# JN5179 register map
Vendor: NXP; Series: JN517x; File version: 20150316
CPU: CM3 r2p1, little endian, no MPU, no FPU, 4 interrupt priority bits
Registers are 32-bit, read-write, reset 0x0 unless marked. A register's access mark holds for its fields unless they carry their own. Offsets are from the block's base; [hi:lo] are bit positions; {n}, {i} and the like mark numbered series.

## SYS_CTRL — System Controller
Base 0x40000000
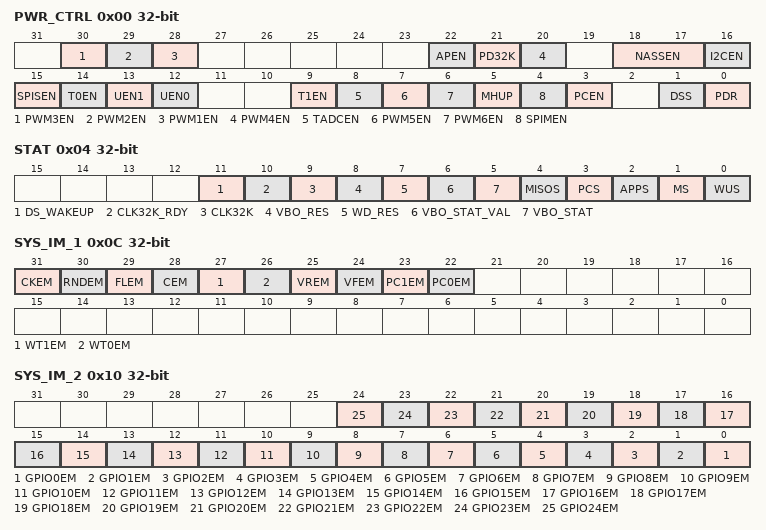
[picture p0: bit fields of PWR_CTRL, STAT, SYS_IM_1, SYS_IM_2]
0x00 PWR_CTRL — Power Control Register
  [30] PWM3EN — Enable PWM3 Timer
    0=Disable (PWM3 Timer is disabled); 1=Enable (PWM3 Timer is enabled)
  [29] PWM2EN — Enable PWM2 Timer
    0=Disable (PWM2 Timer is disabled); 1=Enable (PWM2 Timer is enabled)
  [28] PWM1EN — Enable PWM1 Timer
    0=Disable (PWM1 Timer is disabled); 1=Enable (PWM1 Timer is enabled)
  [22] APEN — Enable Analogue Peripheral Power
    0=Disable (Analogue periperal power is disabled); 1=Enable (Analogue periperal power is enabled)
  [21] PD32K — Power Down 32kHz Oscillator during sleep
    0=Disable (32kHz Oscillator remains powered during sleep); 1=Enable (32kHz Oscillator is powered down during sleep)
  [20] PWM4EN — Enable PWM4 Timer
    0=Disable (PWM4 Timer is disabled); 1=Enable (PWM4 Timer is enabled)
  [18:17] NASSEN — Number of additional SPI slave selects
    0=SPI slave select available for DIO6 (depending on DIO configuration); 1=SPI slave select available for DIO6, DIO15 (depending on DIO configuration); 2=SPI slave select available for DIO6, DIO7 (depending on DIO configuration)
  [16] I2CEN — Enable I2C Interface
    0=Disable (I2C interface is disabled); 1=Enable (I2C interface is enabled)
  [15] SPISEN — Enable SPI Slave
    0=Disable (SPI slave is disabled); 1=Enable (SPI slave is enabled)
  [14] T0EN — Enable Timer 0
    0=Disable (Timer 0 is disabled); 1=Enable (Timer 0 is enabled)
  [13] UEN1 — Enable UART 1
    0=Disable (UART 1 is disabled); 1=Enable (UART 1 is enabled)
  [12] UEN0 — Enable UART 0
    0=Disable (UART 0 is disabled); 1=Enable (UART 0 is enabled)
  [9] T1EN — Enable Timer 1
    0=Disable (Timer 1 is disabled); 1=Enable (Timer 1 is enabled)
  [8] TADCEN — Enable ADC Timer
    0=Disable (ADC timer is disabled); 1=Enable (ADC timer is enabled)
  [7] PWM5EN — Enable PWM5 Timer
    0=Disable (PWM5 timer is disabled); 1=Enable (PWM5 timer is enabled)
  [6] PWM6EN — Enable PWM6 Timer
    0=Disable (PWM6 timer is disabled); 1=Enable (PWM6 timer is enabled)
  [5] MHUP — Memory Hold Up
    0=Disable (RAM is powered down during sleep); 1=Enable (RAM remains powered during sleep)
  [4] SPIMEN — SPI Master Enable
    0=Disable (SPI master disabled); 1=Enable (SPI master enabled)
  [3] PCEN — Protocol Clock Enable
    0=Disable (Protocol clock disabled); 1=Enable (Protocol clock enabled)
  [1] DSS — Deep sleep request
    0=Sleep (Select normal sleep mode); 1=DeepSleep (Select deep sleep mode)
  [0] PDR — Power Down Request (once set the chip begins power down sequence and it must not be cleared)
    0=Disable (Power down not requested); 1=Enable (Power down requested)
0x04 STAT — Device Status Register
  [11] DS_WAKEUP — Deep sleep wake up
    0=Disabled (Normal power up); 1=Enabled (Power up was from deep sleep mode)
  [10] CLK32K_RDY — Status of the 32kHz system clock
    0=Clock is not running; 1=Clock is running satisfactorily
  [9] CLK32K — Instantaneous value of the 32kHz system clock
    0=Clock is low; 1=Clock is high
  [8] VBO_RES — Voltage Brown Out Reset Event
    0=Disabled (Normal power up); 1=Enabled (Power up was proceeded by a voltage brown out)
  [7] WD_RES — Watchdog Reset Event
    0=Disabled (Normal power up); 1=Enabled (Power up was proceeded by a watchdog timeout)
  [6] VBO_STAT_VAL — Voltage Brown Out Status Valid
    0=Disabled (Voltage brown out status is invalid); 1=Enabled (Voltage brown out status is valid)
  [5] VBO_STAT — Voltage Brown Out Status
    0=Disabled (Supply voltage is greater than VBO threshold); 1=Enabled (Supply voltage is lower than VBO threshold)
  [4] MISOS — Value of SPIMISO pin
    0=Disabled (SPIMISO pin is low); 1=Enabled (SPIMISO pin is high)
  [3] PCS — IEEE802.15.4 Radio Clock Status
    0=Disabled (Protocol clock is stopped); 1=Enabled (Protocol clock is running)
  [2] APPS — Analogue Periperhal Power Status
    0=Disabled (Analogue peripherals are powered up); 1=Enabled (Analogue peripherals are powered off)
  [1] MS — Memory Status
    0=MemoryClear (Memory was powered down during sleep); 1=MemoryHeld (Memory was held during sleep)
  [0] WUS — Wake Up Status
    0=ColdStart (Device cold start); 1=WarmStart (Device warm start)
0x0C SYS_IM_1 — System Interrrupt Mask 1 - Enable system controller interrupt sources
  [31] CKEM — Clock Change Event Mask
    0=Disabled (Clock Change Interrupt Disabled); 1=Enabled (Clock Change Interrupt Enabled)
  [30] RNDEM — Random Number Generator Event Mask
    0=Disabled (Random Number Generator Interrupt Disabled); 1=Enabled (Random Number Generator Interrupt Enabled)
  [29] FLEM — Flash Controller Event Mask
    0=Disabled (Flash Controller Interrupt Disabled); 1=Enabled (Flash Controller Interrupt Enabled)
  [28] CEM — Comparator Event Mask
    0=Disabled (Comparator Interrupt Disabled); 1=Enabled (Comparator Interrupt Enabled)
  [27] WT1EM — Wake Up Timer 1 Event Mask
    0=Disabled (Wake Up Timer 1 Interrupt Disabled); 1=Enabled (Wake Up Timer 1 Interrupt Enabled)
  [26] WT0EM — Wake Up Timer 0 Event Mask
    0=Disabled (Wake Up Timer 0 Interrupt Disabled); 1=Enabled (Wake Up Timer 0 Interrupt Enabled)
  [25] VREM — VBO Rising Event Mask (Voltage moved below threshold)
    0=Disabled (VBO Rising Interrupt Disabled); 1=Enabled (VBO Rising Interrupt Enabled)
  [24] VFEM — VBO Falling Event Mask (Voltage moved above threshold)
    0=Disabled (VBO Falling Interrupt Disabled); 1=Enabled (VBO Falling Interrupt Enabled)
  [23] PC1EM — Pulse Counter 1 Event Mask
    0=Disabled (Pulse Counter 1 Interrupt Disabled); 1=Enabled (Pulse Counter 1 Interrupt Enabled)
  [22] PC0EM — Pulse Counter 0 Event Mask
    0=Disabled (Pulse Counter 0 Interrupt Disabled); 1=Enabled (Pulse Counter 0 Interrupt Enabled)
0x10 SYS_IM_2 — System Interrrupt Mask 2 - Enable system controller interrupt sources
  [n] GPIO{n}EM (n=0..24) — GPIO{n} Event Mask
    0=Disabled (GPIO{n} Interrupt Disabled); 1=Enabled (GPIO{n} Interrupt Enabled)
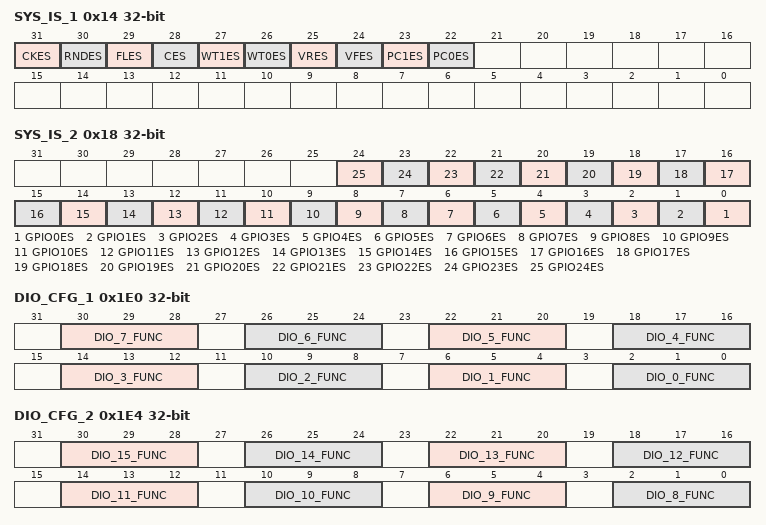
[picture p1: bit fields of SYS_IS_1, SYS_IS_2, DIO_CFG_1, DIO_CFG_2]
0x14 SYS_IS_1 — System Interrrupt Status 1 - system controller interrupt status
  [31] CKES — Clock Change Event Status
    0=Clear (Clock Change No Interrupt); 1=Flagged (Clock Change Interrupt Flagged)
  [30] RNDES — Random Number Generator Event Status
    0=Clear (Random Number Generator No Interrupt); 1=Flagged (Random Number Generator Interrupt Flagged)
  [29] FLES — Flash Controller Event Status
    0=Clear (Flash Controller No Interrupt); 1=Flagged (Flash Controller Interrupt Flagged)
  [28] CES — Comparator Event Status
    0=Clear (Comparator No Interrupt); 1=Flagged (Comparator Interrupt Flagged)
  [27] WT1ES — Wake Up Timer 1 Event Status
    0=Clear (Wake Up Timer 1 No Interrupt); 1=Flagged (Wake Up Timer 1 Interrupt Flagged)
  [26] WT0ES — Wake Up Timer 0 Event Status
    0=Clear (Wake Up Timer 0 No Interrupt); 1=Flagged (Wake Up Timer 0 Interrupt Flagged)
  [25] VRES — VBO Rising Event Status (Voltage moved below threshold)
    0=Clear (VBO Rising No Interrupt); 1=Flagged (VBO Rising Interrupt Flagged)
  [24] VFES — VBO Falling Event Status (Voltage moved above threshold)
    0=Clear (VBO Falling No Interrupt); 1=Flagged (VBO Falling Interrupt Flagged)
  [23] PC1ES — Pulse Counter 1 Event Status
    0=Clear (Pulse Counter 1 No Interrupt); 1=Flagged (Pulse Counter 1 Interrupt Flagged)
  [22] PC0ES — Pulse Counter 0 Event Status
    0=Clear (Pulse Counter 0 No Interrupt); 1=Flagged (Pulse Counter 0 Interrupt Flagged)
0x18 SYS_IS_2 — System Interrrupt Status 2 - system controller interrupt status
  [n] GPIO{n}ES (n=0..24) — GPIO{n} Event Status
    0=Clear (GPIO{n} No Interrupt); 1=Flagged (GPIO{n} Interrupt Flagged)
0x1E0 DIO_CFG_1 — DIO Configuration 1
  [30:28] DIO_7_FUNC — DIO7 Function
    0=GPIO (DIO7 functions as GPIO); 2=SPI_M_MOSI (DIO7 functions as SPI master MOSI); 3=TDI (DIO7 functions as JTAG TDI); 4=SPI_M_SEL2 (DIO7 functions as SPI master chip select 2); 5=SPI_S_SEL (DIO7 functions as SPI slave chip select); 6=COMP_OUT (DIO7 functions as comparator output)
  [26:24] DIO_6_FUNC — DIO6 Function
    0=GPIO (DIO6 functions as GPIO); 1=TIM1_CAP (DIO6 functions as timer 1 capture input); 2=SPI_M_SEL0 (DIO6 functions as SPI master chip select 0); 3=TCK (DIO6 functions as JTAG TCK / SWCK); 4=UART0_CTS (DIO6 functions as UART0 CTS); 5=SPI_S_SCK (DIO6 functions as SPI slave SCK); 7=UART1_RX (DIO6 functions as UART1 RX)
  [22:20] DIO_5_FUNC — DIO5 Function
    0=GPIO (DIO5 functions as GPIO); 1=UART0_TX (DIO5 functions as UART0 TX); 2=TIM0_CAP (DIO5 functions as timer 0 capture intput); 3=I2C_SDA (DIO5 functions as I2C SDA); 4=ADE (DIO5 functions as antenna diversity even output); 5=PC1 (DIO5 functions as pulse counter 1 intput)
  [18:16] DIO_4_FUNC — DIO4 Function
    0=GPIO (DIO4 functions as GPIO); 1=UART0_RX (DIO4 functions as UART0 RX); 2=TIM0_GT (DIO4 functions as timer 0 clock gate); 3=I2C_SCL (DIO4 functions as I2C SCL); 4=ADO (DIO4 functions as antenna diversity odd output)
  [14:12] DIO_3_FUNC — DIO3 Function
    0=GPIO (DIO3 functions as GPIO); 1=RFTX (DIO3 functions as RFTX); 2=TIM0_OUT (DIO3 functions as timer 0 output); 3=I2C_SCL (DIO3 functions as I2C SCL); 5=UART1_TX (DIO3 functions as UART 1 TX); 6=PWM4 (DIO3 functions as PWM4 output)
  [10:8] DIO_2_FUNC — DIO2 Function
    0=GPIO (DIO2 functions as GPIO); 1=RFRX (DIO2 functions as RFRX); 2=TIM0_CAP (DIO2 functions as timer 0 capture input); 3=I2C_SDA (DIO2 functions as I2C SDA); 5=UART1_RX (DIO2 functions as UART 1 RX)
  [6:4] DIO_1_FUNC — DIO1 Function
    0=GPIO (DIO1 functions as GPIO); 1=RFTX (DIO1 functions as RFTX); 3=PC0 (DIO1 functions as pulse counter 0 input)
  [2:0] DIO_0_FUNC — DIO0 Function
    0=GPIO (DIO0 functions as GPIO); 1=RFRX (DIO0 functions as RFRX); 2=SPI_M_SEL0 (DIO0 functions as SPI master chip select 0)
0x1E4 DIO_CFG_2 — DIO Configuration 2
  [30:28] DIO_15_FUNC — DIO15 Function
    0=GPIO (DIO15 functions as GPIO); 1=PWM6 (DIO15 functions as PWM6 output); 2=SPI_M_MOSI (DIO15 functions as SPI master MOSI); 3=TDO (DIO15 functions as JTAG TDO / SWV); 4=SPI_M_SEL1 (DIO15 functions as SPI master chip select 1); 5=TIM0_GT (DIO15 functions as timer 1 clock gate input); 7=BackupClock (DIO15 functions as backup clock)
  [26:24] DIO_14_FUNC — DIO14 Function
    0=GPIO (DIO14 functions as GPIO); 1=PWM3 (DIO14 functions as PWM3 output); 5=PC1 (DIO14 functions as pulse counter 1 input); 6=COMP_OUT (DIO14 functions as comparator output)
  [22:20] DIO_13_FUNC — DIO13 Function
    0=GPIO (DIO13 functions as GPIO); 1=PWM2 (DIO13 functions as PWM2 output); 2=UART0_RX (DIO13 functions as UART0 RX); 5=PC0 (DIO13 functions as pulse counter 0 input)
  [18:16] DIO_12_FUNC — DIO12 Function
    0=GPIO (DIO12 functions as GPIO); 1=PWM1 (DIO12 functions as PWM1 output); 2=UART0_TX (DIO12 functions as UART0 TX)
  [14:12] DIO_11_FUNC — DIO11 Function
    0=GPIO (DIO11 functions as GPIO); 1=TIM1_OUT (DIO11 functions as timer 1 output); 2=SPI_M_CLK (DIO11 functions as SPI master SCK); 3=TMS (DIO11 functions as JTAG TMS / SWD); 4=UART0_RTS (DIO11 functions as UART0 RTS); 5=SPI_S_MOSI (DIO11 functions as SPI master MOSI); 6=UART1_TX (DIO11 functions as UART1 TX)
  [10:8] DIO_10_FUNC — DIO10 Function
    0=GPIO (DIO10 functions as GPIO); 1=UART0_RX (DIO10 functions as UART0 RX); 3=TDI (DIO10 functions as JTAG TDI)
  [6:4] DIO_9_FUNC — DIO9 Function
    0=GPIO (DIO9 functions as GPIO); 1=UART0_TX (DIO9 functions as UART0 TX); 3=TDO (DIO9 functions as JTAG TDO / SWV)
  [2:0] DIO_8_FUNC — DIO8 Function
    0=GPIO (DIO8 functions as GPIO); 1=PWM5 (DIO8 functions as PWM5 output); 2=TIM0_OUT (DIO8 functions as timer 0 output)
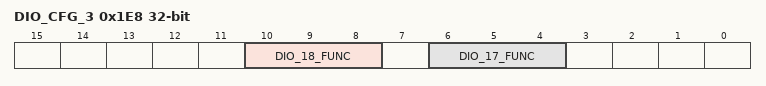
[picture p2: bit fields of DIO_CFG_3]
0x1E8 DIO_CFG_3 — DIO Configuration 3
  [10:8] DIO_18_FUNC — DIO18 Function
    0=GPIO (DIO18 functions as GPIO); 1=TIM1_OUT (DIO18 functions as timer 1 output); 2=SPI_M_MISO (DIO18 functions as SPI master MISO); 3=TMS (DIO18 functions as JTAG TMS / SWD)
  [6:4] DIO_17_FUNC — DIO17 Function
    0=GPIO (DIO17 functions as GPIO); 1=TIM1_CAP (DIO17 functions as timer 1 capture input); 2=SPI_M_SEL0 (DIO17 functions as SPI master chip select 0); 3=TCK (DIO17 functions as JTAG TCK / SWCK)
